AUTOSAR XML (schema 4-3-0)
standard types defined: boolean, float32, float64, sint16, sint32, sint8, uint16, uint32, uint8, uint64, sint64
package /ARPackage_0/Pkg_Cluster
  can cluster Can_Network: protocol-name=CAN
    can physical channel Can_Network_Channel: comm-connectors=[Conn_Can_Network_CANNODE_0_AUT, Conn_Can_Network_CANNODE_0_REF_ECU]
      frame F_STD_0x302: id 0x302, from REF_ECU, to AUT, frame-length=2, can-addressing-mode=STANDARD, can-frame-rx-behavior=ANY
        carries pdu F_STD_0x302: packing-byte-order=big-endian, start-position=0, update-indication-bit-position=-1
        pdu F_STD_0x302: length=2, transmission-mode-condition{data-filter={data-filter-type=NEW-IS-WITHIN, max=32767, min=-32768, offset=0}, i-signal-in-i-pdu=S_STD_0x302_S16}, transmission-mode-false-timing=cyclic-timing={time-offset=0.0, time-period=0.1}, transmission-mode-true-timing=cyclic-timing={time-offset=0.0, time-period=0.1}
          signal S_STD_0x302_S16: start 7, 16 bit, big-endian, base-type=sint16, compu {raw=phys for phys -32768..32767}, update-indication-bit-position=-1, to AUT
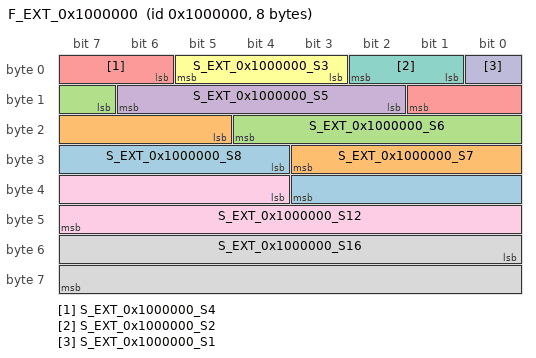
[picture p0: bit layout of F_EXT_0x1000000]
      frame F_EXT_0x1000000: id 0x1000000, from REF_ECU, to AUT, frame-length=8, can-addressing-mode=EXTENDED, can-frame-rx-behavior=ANY
        carries pdu F_EXT_0x1000000: packing-byte-order=little-endian, start-position=0, update-indication-bit-position=-1
        pdu F_EXT_0x1000000: length=8, transmission-mode-false-timing=cyclic-timing={time-offset=0.0, time-period=0.1}, transmission-mode-true-timing=cyclic-timing={time-offset=0.0, time-period=0.1}
          transmission-mode-conditions:
            {data-filter={data-filter-type=ALWAYS, max=255, min=0, offset=0}, i-signal-in-i-pdu=S_EXT_0x1000000_S8}
            {data-filter={data-filter-type=ALWAYS, max=127, min=0, offset=0}, i-signal-in-i-pdu=S_EXT_0x1000000_S7}
            {data-filter={data-filter-type=ALWAYS, max=63, min=0, offset=0}, i-signal-in-i-pdu=S_EXT_0x1000000_S6}
            {data-filter={data-filter-type=ALWAYS, max=31, min=0, offset=0}, i-signal-in-i-pdu=S_EXT_0x1000000_S5}
            {data-filter={data-filter-type=ALWAYS, max=15, min=0, offset=0}, i-signal-in-i-pdu=S_EXT_0x1000000_S4}
            {data-filter={data-filter-type=ALWAYS, max=7, min=0, offset=0}, i-signal-in-i-pdu=S_EXT_0x1000000_S3}
            {data-filter={data-filter-type=ALWAYS, max=3, min=0, offset=0}, i-signal-in-i-pdu=S_EXT_0x1000000_S2}
            {data-filter={data-filter-type=NEW-IS-WITHIN, max=65535, min=0, offset=0}, i-signal-in-i-pdu=S_EXT_0x1000000_S16}
            {data-filter={data-filter-type=NEW-IS-WITHIN, max=4095, min=0, offset=0}, i-signal-in-i-pdu=S_EXT_0x1000000_S12}
            {data-filter={data-filter-type=ALWAYS, max=1, min=0, offset=0}, i-signal-in-i-pdu=S_EXT_0x1000000_S1}
          signal S_EXT_0x1000000_S8: start 28, 8 bit, little-endian, base-type=uint8, compu {raw=phys for phys 0..255}, update-indication-bit-position=-1, to AUT
          signal S_EXT_0x1000000_S7: start 21, 7 bit, little-endian, base-type=uint8, compu {raw=phys for phys 0..127}, update-indication-bit-position=-1, to AUT
          signal S_EXT_0x1000000_S6: start 15, 6 bit, little-endian, base-type=uint8, compu {raw=phys for phys 0..63}, update-indication-bit-position=-1, to AUT
          signal S_EXT_0x1000000_S5: start 10, 5 bit, little-endian, base-type=uint8, compu {raw=phys for phys 0..31}, update-indication-bit-position=-1, to AUT
          signal S_EXT_0x1000000_S4: start 6, 4 bit, little-endian, base-type=uint8, compu {raw=phys for phys 0..15}, update-indication-bit-position=-1, to AUT
          signal S_EXT_0x1000000_S3: start 3, 3 bit, little-endian, base-type=uint8, compu {raw=phys for phys 0..7}, update-indication-bit-position=-1, to AUT
          signal S_EXT_0x1000000_S2: start 1, 2 bit, little-endian, base-type=uint8, compu {raw=phys for phys 0..3}, update-indication-bit-position=-1, to AUT
          signal S_EXT_0x1000000_S16: start 48, 16 bit, little-endian, base-type=uint16, compu {raw=phys for phys 0..65535}, update-indication-bit-position=-1, to AUT
          signal S_EXT_0x1000000_S12: start 36, 12 bit, little-endian, base-type=uint16, compu {raw=phys for phys 0..4095}, update-indication-bit-position=-1, to AUT
          signal S_EXT_0x1000000_S1: start 0, 1 bit, little-endian, base-type=uint8, compu {raw=phys for phys 0..1}, update-indication-bit-position=-1, to AUT
      frame F_STD_0x303: id 0x303, from REF_ECU, to AUT, frame-length=3, can-addressing-mode=STANDARD, can-frame-rx-behavior=ANY
        carries pdu F_STD_0x303: packing-byte-order=big-endian, start-position=0, update-indication-bit-position=-1
        pdu F_STD_0x303: length=3, transmission-mode-condition{data-filter={data-filter-type=NEW-IS-WITHIN, max=8388607, min=-8388608, offset=0}, i-signal-in-i-pdu=S_STD_0x303_S24}, transmission-mode-false-timing=cyclic-timing={time-offset=0.0, time-period=0.1}, transmission-mode-true-timing=cyclic-timing={time-offset=0.0, time-period=0.1}
          signal S_STD_0x303_S24: start 7, 24 bit, big-endian, base-type=sint32, compu {raw=phys for phys -8388608..8388607}, update-indication-bit-position=-1, to AUT
      frame F_STD_0x304: id 0x304, from REF_ECU, to AUT, frame-length=4, can-addressing-mode=STANDARD, can-frame-rx-behavior=ANY
        carries pdu F_STD_0x304: packing-byte-order=big-endian, start-position=0, update-indication-bit-position=-1
        pdu F_STD_0x304: length=4, transmission-mode-condition{data-filter={data-filter-type=NEW-IS-WITHIN, max=4294967295, min=0, offset=0}, i-signal-in-i-pdu=S_STD_0x304_S32}, transmission-mode-false-timing=cyclic-timing={time-offset=0.0, time-period=0.1}, transmission-mode-true-timing=cyclic-timing={time-offset=0.0, time-period=0.1}
          signal S_STD_0x304_S32: start 7, 32 bit, big-endian, base-type=uint32, compu {raw=phys for phys 0..4294967295}, update-indication-bit-position=-1, to AUT
      frame F_STD_0x305: id 0x305, from REF_ECU, to AUT, frame-length=5, can-addressing-mode=STANDARD, can-frame-rx-behavior=ANY
        carries pdu F_STD_0x305: packing-byte-order=big-endian, start-position=0, update-indication-bit-position=-1
        pdu F_STD_0x305: length=5, transmission-mode-false-timing=cyclic-timing={time-offset=0.0, time-period=0.1}, transmission-mode-true-timing=cyclic-timing={time-offset=0.0, time-period=0.1}
          transmission-mode-conditions:
            {data-filter={data-filter-type=ALWAYS, max=255, min=0, offset=0}, i-signal-in-i-pdu=S_STD_0x305_S8}
            {data-filter={data-filter-type=NEW-IS-WITHIN, max=2147483647, min=-2147483648, offset=0}, i-signal-in-i-pdu=S_STD_0x305_S32}
          signal S_STD_0x305_S8: start 39, 8 bit, big-endian, base-type=uint8, compu {raw=phys for phys 0..255}, update-indication-bit-position=-1, to AUT
          signal S_STD_0x305_S32: start 7, 32 bit, big-endian, base-type=sint32, compu {raw=phys for phys -2147483648..2147483647}, update-indication-bit-position=-1, to AUT
      frame F_STD_0x306: id 0x306, from REF_ECU, to AUT, frame-length=6, can-addressing-mode=STANDARD, can-frame-rx-behavior=ANY
        carries pdu F_STD_0x306: packing-byte-order=big-endian, start-position=0, update-indication-bit-position=-1
        pdu F_STD_0x306: length=6, transmission-mode-false-timing=cyclic-timing={time-offset=0.0, time-period=0.1}, transmission-mode-true-timing=cyclic-timing={time-offset=0.0, time-period=0.1}
          transmission-mode-conditions:
            {data-filter={data-filter-type=NEW-IS-WITHIN, max=65535, min=0, offset=0}, i-signal-in-i-pdu=S_STD_0x306_S16}
            {data-filter={data-filter-type=NEW-IS-WITHIN, max=2147483647, min=-2147483648, offset=0}, i-signal-in-i-pdu=S_STD_0x306_S32}
          signal S_STD_0x306_S16: start 39, 16 bit, big-endian, base-type=uint16, compu {raw=phys for phys 0..65535}, update-indication-bit-position=-1, to AUT
          signal S_STD_0x306_S32: start 7, 32 bit, big-endian, base-type=sint32, compu {raw=phys for phys -2147483648..2147483647}, update-indication-bit-position=-1, to AUT
      frame F_STD_0x307: id 0x307, from REF_ECU, to AUT, frame-length=7, can-addressing-mode=STANDARD, can-frame-rx-behavior=ANY
        carries pdu F_STD_0x307: packing-byte-order=big-endian, start-position=0, update-indication-bit-position=-1
        pdu F_STD_0x307: length=7, transmission-mode-false-timing=cyclic-timing={time-offset=0.0, time-period=0.1}, transmission-mode-true-timing=cyclic-timing={time-offset=0.0, time-period=0.1}
          transmission-mode-conditions:
            {data-filter={data-filter-type=NEW-IS-WITHIN, max=8388607, min=-8388608, offset=0}, i-signal-in-i-pdu=S_STD_0x307_S24}
            {data-filter={data-filter-type=NEW-IS-WITHIN, max=2147483647, min=-2147483648, offset=0}, i-signal-in-i-pdu=S_STD_0x307_S32}
          signal S_STD_0x307_S24: start 39, 24 bit, big-endian, base-type=sint32, compu {raw=phys for phys -8388608..8388607}, update-indication-bit-position=-1, to AUT
          signal S_STD_0x307_S32: start 7, 32 bit, big-endian, base-type=sint32, compu {raw=phys for phys -2147483648..2147483647}, update-indication-bit-position=-1, to AUT
      frame F_STD_0x308: id 0x308, from REF_ECU, to AUT, frame-length=8, can-addressing-mode=STANDARD, can-frame-rx-behavior=ANY
        carries pdu F_STD_0x308: packing-byte-order=big-endian, start-position=0, update-indication-bit-position=-1
        pdu F_STD_0x308: length=8, transmission-mode-false-timing=cyclic-timing={time-offset=0.0, time-period=0.1}, transmission-mode-true-timing=cyclic-timing={time-offset=0.0, time-period=0.1}
          transmission-mode-conditions:
            {data-filter={data-filter-type=NEW-IS-WITHIN, max=32767, min=-32768, offset=0}, i-signal-in-i-pdu=S_STD_0x308_2_S32}
            {data-filter={data-filter-type=NEW-IS-WITHIN, max=32767, min=-32768, offset=0}, i-signal-in-i-pdu=S_STD_0x308_1_S32}
          signal S_STD_0x308_2_S32: start 39, 32 bit, big-endian, base-type=sint32, compu {raw=phys for phys -32768..32767}, update-indication-bit-position=-1, to AUT
          signal S_STD_0x308_1_S32: start 0, 32 bit, little-endian, base-type=sint32, compu {raw=phys for phys -32768..32767}, update-indication-bit-position=-1, to AUT
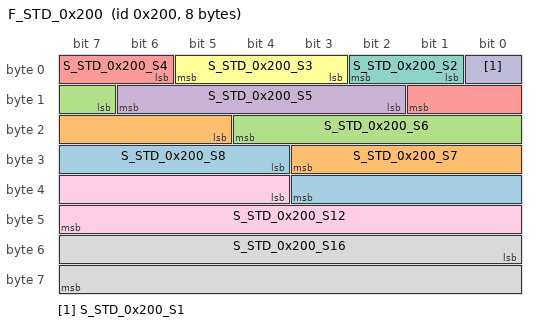
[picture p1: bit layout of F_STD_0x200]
      frame F_STD_0x200: id 0x200, from REF_ECU, to AUT, frame-length=8, can-addressing-mode=STANDARD, can-frame-rx-behavior=ANY
        carries pdu F_STD_0x200: packing-byte-order=little-endian, start-position=0, update-indication-bit-position=-1
        pdu F_STD_0x200: length=8, transmission-mode-false-timing=cyclic-timing={time-offset=0.0, time-period=0.1}, transmission-mode-true-timing=cyclic-timing={time-offset=0.0, time-period=0.1}
          transmission-mode-conditions:
            {data-filter={data-filter-type=ALWAYS, max=255, min=0, offset=0}, i-signal-in-i-pdu=S_STD_0x200_S8}
            {data-filter={data-filter-type=ALWAYS, max=127, min=0, offset=0}, i-signal-in-i-pdu=S_STD_0x200_S7}
            {data-filter={data-filter-type=ALWAYS, max=63, min=0, offset=0}, i-signal-in-i-pdu=S_STD_0x200_S6}
            {data-filter={data-filter-type=ALWAYS, max=31, min=0, offset=0}, i-signal-in-i-pdu=S_STD_0x200_S5}
            {data-filter={data-filter-type=ALWAYS, max=15, min=0, offset=0}, i-signal-in-i-pdu=S_STD_0x200_S4}
            {data-filter={data-filter-type=ALWAYS, max=7, min=0, offset=0}, i-signal-in-i-pdu=S_STD_0x200_S3}
            {data-filter={data-filter-type=ALWAYS, max=3, min=0, offset=0}, i-signal-in-i-pdu=S_STD_0x200_S2}
            {data-filter={data-filter-type=NEW-IS-WITHIN, max=65535, min=0, offset=2}, i-signal-in-i-pdu=S_STD_0x200_S16}
            {data-filter={data-filter-type=NEW-IS-WITHIN, max=4095, min=0, offset=0}, i-signal-in-i-pdu=S_STD_0x200_S12}
            {data-filter={data-filter-type=ALWAYS, max=1, min=0, offset=0}, i-signal-in-i-pdu=S_STD_0x200_S1}
          signal S_STD_0x200_S8: start 28, 8 bit, little-endian, base-type=uint8, compu {raw=phys for phys 0..255}, update-indication-bit-position=-1, to AUT
          signal S_STD_0x200_S7: start 21, 7 bit, little-endian, base-type=uint8, compu {raw=phys for phys 0..127}, update-indication-bit-position=-1, to AUT
          signal S_STD_0x200_S6: start 15, 6 bit, little-endian, base-type=uint8, compu {raw=phys for phys 0..63}, update-indication-bit-position=-1, to AUT
          signal S_STD_0x200_S5: start 10, 5 bit, little-endian, base-type=uint8, compu {raw=phys for phys 0..31}, update-indication-bit-position=-1, to AUT
          signal S_STD_0x200_S4: start 6, 4 bit, little-endian, base-type=uint8, compu {raw=phys for phys 0..15}, update-indication-bit-position=-1, to AUT
          signal S_STD_0x200_S3: start 3, 3 bit, little-endian, base-type=uint8, compu {raw=phys for phys 0..7}, update-indication-bit-position=-1, to AUT
          signal S_STD_0x200_S2: start 1, 2 bit, little-endian, base-type=uint8, compu {raw=phys for phys 0..3}, update-indication-bit-position=-1, to AUT
          signal S_STD_0x200_S16: start 48, 16 bit, little-endian, base-type=uint16, compu {raw=phys*0.5-1 for phys 2..131072}, update-indication-bit-position=-1, to AUT
          signal S_STD_0x200_S12: start 36, 12 bit, little-endian, base-type=uint16, compu {raw=phys for phys 0..4095}, update-indication-bit-position=-1, to AUT
          signal S_STD_0x200_S1: start 0, 1 bit, little-endian, base-type=uint8, compu {raw=phys for phys 0..1}, update-indication-bit-position=-1, to AUT
      frame F_STD_0x201: id 0x201, from REF_ECU, to AUT, frame-length=1, can-addressing-mode=STANDARD, can-frame-rx-behavior=ANY
        carries pdu F_STD_0x201: packing-byte-order=little-endian, start-position=0, update-indication-bit-position=-1
        pdu F_STD_0x201: length=1, transmission-mode-condition{data-filter={data-filter-type=ALWAYS, max=255, min=0, offset=0}, i-signal-in-i-pdu=S_STD_0x201_S8}, transmission-mode-false-timing=cyclic-timing={time-offset=0.0, time-period=0.1}, transmission-mode-true-timing=cyclic-timing={time-offset=0.0, time-period=0.1}
          signal S_STD_0x201_S8: start 0, 8 bit, little-endian, base-type=uint8, compu {raw=phys for phys 0..255}, update-indication-bit-position=-1, to AUT
      frame F_STD_0x202: id 0x202, from REF_ECU, to AUT, frame-length=2, can-addressing-mode=STANDARD, can-frame-rx-behavior=ANY
        carries pdu F_STD_0x202: packing-byte-order=little-endian, start-position=0, update-indication-bit-position=-1
        pdu F_STD_0x202: length=2, transmission-mode-condition{data-filter={data-filter-type=NEW-IS-WITHIN, max=65535, min=0, offset=0}, i-signal-in-i-pdu=S_STD_0x202_S16}, transmission-mode-false-timing=cyclic-timing={time-offset=0.0, time-period=0.1}, transmission-mode-true-timing=cyclic-timing={time-offset=0.0, time-period=0.1}
          signal S_STD_0x202_S16: start 0, 16 bit, little-endian, base-type=uint16, compu {raw=phys for phys 0..65535}, update-indication-bit-position=-1, to AUT
      frame F_STD_0x203: id 0x203, from REF_ECU, to AUT, frame-length=3, can-addressing-mode=STANDARD, can-frame-rx-behavior=ANY
        carries pdu F_STD_0x203: packing-byte-order=little-endian, start-position=0, update-indication-bit-position=-1
        pdu F_STD_0x203: length=3, transmission-mode-condition{data-filter={data-filter-type=NEW-IS-WITHIN, max=16777215, min=0, offset=0}, i-signal-in-i-pdu=S_STD_0x203_S24}, transmission-mode-false-timing=cyclic-timing={time-offset=0.0, time-period=0.1}, transmission-mode-true-timing=cyclic-timing={time-offset=0.0, time-period=0.1}
          signal S_STD_0x203_S24: start 0, 24 bit, little-endian, base-type=uint32, compu {raw=phys for phys 0..16777215}, update-indication-bit-position=-1, to AUT
      frame F_STD_0x204: id 0x204, from REF_ECU, to AUT, frame-length=4, can-addressing-mode=STANDARD, can-frame-rx-behavior=ANY
        carries pdu F_STD_0x204: packing-byte-order=little-endian, start-position=0, update-indication-bit-position=-1
        pdu F_STD_0x204: length=4, transmission-mode-condition{data-filter={data-filter-type=NEW-IS-WITHIN, max=2147483647, min=-2147483648, offset=0}, i-signal-in-i-pdu=S_STD_0x204_S32}, transmission-mode-false-timing=cyclic-timing={time-offset=0.0, time-period=0.1}, transmission-mode-true-timing=cyclic-timing={time-offset=0.0, time-period=0.1}
          signal S_STD_0x204_S32: start 0, 32 bit, little-endian, base-type=sint32, compu {raw=phys for phys -2147483648..2147483647}, update-indication-bit-position=-1, to AUT
      frame F_EXT_0x1000005: id 0x1000005, from REF_ECU, to AUT, frame-length=5, can-addressing-mode=EXTENDED, can-frame-rx-behavior=ANY
        carries pdu F_EXT_0x1000005: packing-byte-order=little-endian, start-position=0, update-indication-bit-position=-1
        pdu F_EXT_0x1000005: length=5, transmission-mode-false-timing=cyclic-timing={time-offset=0.0, time-period=0.1}, transmission-mode-true-timing=cyclic-timing={time-offset=0.0, time-period=0.1}
          transmission-mode-conditions:
            {data-filter={data-filter-type=NEW-IS-WITHIN, max=127, min=-128, offset=0}, i-signal-in-i-pdu=S_EXT_0x1000005_S8}
            {data-filter={data-filter-type=NEW-IS-WITHIN, max=4294967295, min=0, offset=0}, i-signal-in-i-pdu=S_EXT_0x1000005_S32}
          signal S_EXT_0x1000005_S8: start 32, 8 bit, little-endian, base-type=sint8, compu {raw=phys for phys -128..127}, update-indication-bit-position=-1, to AUT
          signal S_EXT_0x1000005_S32: start 0, 32 bit, little-endian, base-type=uint32, compu {raw=phys for phys 0..4294967295}, update-indication-bit-position=-1, to AUT
      frame F_STD_0x205: id 0x205, from REF_ECU, to AUT, frame-length=5, can-addressing-mode=STANDARD, can-frame-rx-behavior=ANY
        carries pdu F_STD_0x205: packing-byte-order=little-endian, start-position=0, update-indication-bit-position=-1
        pdu F_STD_0x205: length=5, transmission-mode-false-timing=cyclic-timing={time-offset=0.0, time-period=0.1}, transmission-mode-true-timing=cyclic-timing={time-offset=0.0, time-period=0.1}
          transmission-mode-conditions:
            {data-filter={data-filter-type=NEW-IS-WITHIN, max=127, min=-128, offset=0}, i-signal-in-i-pdu=S_STD_0x205_S8}
            {data-filter={data-filter-type=NEW-IS-WITHIN, max=4294970000, min=0, offset=0}, i-signal-in-i-pdu=S_STD_0x205_S32}
          signal S_STD_0x205_S8: start 32, 8 bit, little-endian, base-type=sint8, compu {raw=phys for phys -128..127}, update-indication-bit-position=-1, to AUT
          signal S_STD_0x205_S32: start 0, 32 bit, little-endian, base-type=uint32, compu {raw=phys for phys 0..4294970000}, update-indication-bit-position=-1, to AUT
      frame F_EXT_0x1000003: id 0x1000003, from REF_ECU, to AUT, frame-length=3, can-addressing-mode=EXTENDED, can-frame-rx-behavior=ANY
        carries pdu F_EXT_0x1000003: packing-byte-order=little-endian, start-position=0, update-indication-bit-position=-1
        pdu F_EXT_0x1000003: length=3, transmission-mode-condition{data-filter={data-filter-type=NEW-IS-WITHIN, max=16777215, min=0, offset=0}, i-signal-in-i-pdu=S_EXT_0x1000003_S24}, transmission-mode-false-timing=cyclic-timing={time-offset=0.0, time-period=0.1}, transmission-mode-true-timing=cyclic-timing={time-offset=0.0, time-period=0.1}
          signal S_EXT_0x1000003_S24: start 0, 24 bit, little-endian, base-type=uint32, compu {raw=phys for phys 0..16777215}, update-indication-bit-position=-1, to AUT
      frame F_STD_0x206: id 0x206, from REF_ECU, to AUT, frame-length=6, can-addressing-mode=STANDARD, can-frame-rx-behavior=ANY
        carries pdu F_STD_0x206: packing-byte-order=little-endian, start-position=0, update-indication-bit-position=-1
        pdu F_STD_0x206: length=6, transmission-mode-false-timing=cyclic-timing={time-offset=0.0, time-period=0.1}, transmission-mode-true-timing=cyclic-timing={time-offset=0.0, time-period=0.1}
          transmission-mode-conditions:
            {data-filter={data-filter-type=NEW-IS-WITHIN, max=32767, min=-32768, offset=0}, i-signal-in-i-pdu=S_STD_0x206_S16}
            {data-filter={data-filter-type=NEW-IS-WITHIN, max=4294967295, min=0, offset=0}, i-signal-in-i-pdu=S_STD_0x206_S32}
          signal S_STD_0x206_S16: start 32, 16 bit, little-endian, base-type=sint16, compu {raw=phys for phys -32768..32767}, update-indication-bit-position=-1, to AUT
          signal S_STD_0x206_S32: start 0, 32 bit, little-endian, base-type=uint32, compu {raw=phys for phys 0..4294967295}, update-indication-bit-position=-1, to AUT
      frame F_EXT_0x1000004: id 0x1000004, from REF_ECU, to AUT, frame-length=4, can-addressing-mode=EXTENDED, can-frame-rx-behavior=ANY
        carries pdu F_EXT_0x1000004: packing-byte-order=little-endian, start-position=0, update-indication-bit-position=-1
        pdu F_EXT_0x1000004: length=4, transmission-mode-condition{data-filter={data-filter-type=NEW-IS-WITHIN, max=2147483647, min=-2147483648, offset=0}, i-signal-in-i-pdu=S_EXT_0x1000004_S32}, transmission-mode-false-timing=cyclic-timing={time-offset=0.0, time-period=0.1}, transmission-mode-true-timing=cyclic-timing={time-offset=0.0, time-period=0.1}
          signal S_EXT_0x1000004_S32: start 0, 32 bit, little-endian, base-type=sint32, compu {raw=phys for phys -2147483648..2147483647}, update-indication-bit-position=-1, to AUT
      frame F_STD_0x207: id 0x207, from REF_ECU, to AUT, frame-length=7, can-addressing-mode=STANDARD, can-frame-rx-behavior=ANY
        carries pdu F_STD_0x207: packing-byte-order=little-endian, start-position=0, update-indication-bit-position=-1
        pdu F_STD_0x207: length=7, transmission-mode-false-timing=cyclic-timing={time-offset=0.0, time-period=0.1}, transmission-mode-true-timing=cyclic-timing={time-offset=0.0, time-period=0.1}
          transmission-mode-conditions:
            {data-filter={data-filter-type=NEW-IS-WITHIN, max=16777215, min=0, offset=0}, i-signal-in-i-pdu=S_STD_0x207_S24}
            {data-filter={data-filter-type=NEW-IS-WITHIN, max=4294970000, min=0, offset=0}, i-signal-in-i-pdu=S_STD_0x207_S32}
          signal S_STD_0x207_S24: start 32, 24 bit, little-endian, base-type=uint32, compu {raw=phys for phys 0..16777215}, update-indication-bit-position=-1, to AUT
          signal S_STD_0x207_S32: start 0, 32 bit, little-endian, base-type=uint32, compu {raw=phys for phys 0..4294970000}, update-indication-bit-position=-1, to AUT
      frame F_EXT_0x1000001: id 0x1000001, from REF_ECU, to AUT, frame-length=1, can-addressing-mode=EXTENDED, can-frame-rx-behavior=ANY
        carries pdu F_EXT_0x1000001: packing-byte-order=little-endian, start-position=0, update-indication-bit-position=-1
        pdu F_EXT_0x1000001: length=1, transmission-mode-condition{data-filter={data-filter-type=ALWAYS, max=255, min=0, offset=0}, i-signal-in-i-pdu=S_EXT_0x1000001_S8}, transmission-mode-false-timing=cyclic-timing={time-offset=0.0, time-period=0.1}, transmission-mode-true-timing=cyclic-timing={time-offset=0.0, time-period=0.1}
          signal S_EXT_0x1000001_S8: start 0, 8 bit, little-endian, base-type=uint8, compu {raw=phys for phys 0..255}, update-indication-bit-position=-1, to AUT
      frame F_EXT_0x1000002: id 0x1000002, from REF_ECU, to AUT, frame-length=2, can-addressing-mode=EXTENDED, can-frame-rx-behavior=ANY
        carries pdu F_EXT_0x1000002: packing-byte-order=little-endian, start-position=0, update-indication-bit-position=-1
        pdu F_EXT_0x1000002: length=2, transmission-mode-condition{data-filter={data-filter-type=NEW-IS-WITHIN, max=65535, min=0, offset=0}, i-signal-in-i-pdu=S_EXT_0x1000002_S16}, transmission-mode-false-timing=cyclic-timing={time-offset=0.0, time-period=0.1}, transmission-mode-true-timing=cyclic-timing={time-offset=0.0, time-period=0.1}
          signal S_EXT_0x1000002_S16: start 0, 16 bit, little-endian, base-type=uint16, compu {raw=phys for phys 0..65535}, update-indication-bit-position=-1, to AUT
      frame F_EXT_0x2000006: id 0x2000006, from REF_ECU, to AUT, frame-length=6, can-addressing-mode=EXTENDED, can-frame-rx-behavior=ANY
        carries pdu F_EXT_0x2000006: packing-byte-order=big-endian, start-position=0, update-indication-bit-position=-1
        pdu F_EXT_0x2000006: length=6, transmission-mode-false-timing=cyclic-timing={time-offset=0.0, time-period=0.1}, transmission-mode-true-timing=cyclic-timing={time-offset=0.0, time-period=0.1}
          transmission-mode-conditions:
            {data-filter={data-filter-type=NEW-IS-WITHIN, max=65535, min=0, offset=0}, i-signal-in-i-pdu=S_EXT_0x2000006_S16}
            {data-filter={data-filter-type=NEW-IS-WITHIN, max=2147483647, min=-2147483648, offset=0}, i-signal-in-i-pdu=S_EXT_0x2000006_S32}
          signal S_EXT_0x2000006_S16: start 39, 16 bit, big-endian, base-type=uint16, compu {raw=phys for phys 0..65535}, update-indication-bit-position=-1, to AUT
          signal S_EXT_0x2000006_S32: start 7, 32 bit, big-endian, base-type=sint32, compu {raw=phys for phys -2147483648..2147483647}, update-indication-bit-position=-1, to AUT
      frame F_EXT_0x2000005: id 0x2000005, from REF_ECU, to AUT, frame-length=5, can-addressing-mode=EXTENDED, can-frame-rx-behavior=ANY
        carries pdu F_EXT_0x2000005: packing-byte-order=big-endian, start-position=0, update-indication-bit-position=-1
        pdu F_EXT_0x2000005: length=5, transmission-mode-false-timing=cyclic-timing={time-offset=0.0, time-period=0.1}, transmission-mode-true-timing=cyclic-timing={time-offset=0.0, time-period=0.1}
          transmission-mode-conditions:
            {data-filter={data-filter-type=ALWAYS, max=255, min=0, offset=0}, i-signal-in-i-pdu=S_EXT_0x2000005_S8}
            {data-filter={data-filter-type=NEW-IS-WITHIN, max=2147483647, min=-2147483648, offset=0}, i-signal-in-i-pdu=S_EXT_0x2000005_S32}
          signal S_EXT_0x2000005_S8: start 39, 8 bit, big-endian, base-type=uint8, compu {raw=phys for phys 0..255}, update-indication-bit-position=-1, to AUT
          signal S_EXT_0x2000005_S32: start 7, 32 bit, big-endian, base-type=sint32, compu {raw=phys for phys -2147483648..2147483647}, update-indication-bit-position=-1, to AUT
      frame F_EXT_0x2000008: id 0x2000008, from REF_ECU, to AUT, frame-length=8, can-addressing-mode=EXTENDED, can-frame-rx-behavior=ANY
        carries pdu F_EXT_0x2000008: packing-byte-order=big-endian, start-position=0, update-indication-bit-position=-1
        pdu F_EXT_0x2000008: length=8, transmission-mode-false-timing=cyclic-timing={time-offset=0.0, time-period=0.1}, transmission-mode-true-timing=cyclic-timing={time-offset=0.0, time-period=0.1}
          transmission-mode-conditions:
            {data-filter={data-filter-type=NEW-IS-WITHIN, max=32767, min=-32768, offset=0}, i-signal-in-i-pdu=S_EXT_0x2000008_2_S32}
            {data-filter={data-filter-type=NEW-IS-WITHIN, max=32767, min=-32768, offset=0}, i-signal-in-i-pdu=S_EXT_0x2000008_1_S32}
          signal S_EXT_0x2000008_2_S32: start 39, 32 bit, big-endian, base-type=sint32, compu {raw=phys for phys -32768..32767}, update-indication-bit-position=-1, to AUT
          signal S_EXT_0x2000008_1_S32: start 0, 32 bit, little-endian, base-type=sint32, compu {raw=phys for phys -32768..32767}, update-indication-bit-position=-1, to AUT
      frame F_EXT_0x2000007: id 0x2000007, from REF_ECU, to AUT, frame-length=7, can-addressing-mode=EXTENDED, can-frame-rx-behavior=ANY
        carries pdu F_EXT_0x2000007: packing-byte-order=big-endian, start-position=0, update-indication-bit-position=-1
        pdu F_EXT_0x2000007: length=7, transmission-mode-false-timing=cyclic-timing={time-offset=0.0, time-period=0.1}, transmission-mode-true-timing=cyclic-timing={time-offset=0.0, time-period=0.1}
          transmission-mode-conditions:
            {data-filter={data-filter-type=NEW-IS-WITHIN, max=8388607, min=-8388608, offset=0}, i-signal-in-i-pdu=S_EXT_0x2000007_S24}
            {data-filter={data-filter-type=NEW-IS-WITHIN, max=2147483647, min=-2147483648, offset=0}, i-signal-in-i-pdu=S_EXT_0x2000007_S32}
          signal S_EXT_0x2000007_S24: start 39, 24 bit, big-endian, base-type=sint32, compu {raw=phys for phys -8388608..8388607}, update-indication-bit-position=-1, to AUT
          signal S_EXT_0x2000007_S32: start 7, 32 bit, big-endian, base-type=sint32, compu {raw=phys for phys -2147483648..2147483647}, update-indication-bit-position=-1, to AUT
      frame F_EXT_0x1000008: id 0x1000008, from REF_ECU, to AUT, frame-length=8, can-addressing-mode=EXTENDED, can-frame-rx-behavior=ANY
        carries pdu F_EXT_0x1000008: packing-byte-order=little-endian, start-position=0, update-indication-bit-position=-1
        pdu F_EXT_0x1000008: length=8, transmission-mode-false-timing=cyclic-timing={time-offset=0.0, time-period=0.1}, transmission-mode-true-timing=cyclic-timing={time-offset=0.0, time-period=0.1}
          transmission-mode-conditions:
            {data-filter={data-filter-type=NEW-IS-WITHIN, max=4294967295, min=0, offset=0}, i-signal-in-i-pdu=S_EXT_0x1000008_2_S32}
            {data-filter={data-filter-type=NEW-IS-WITHIN, max=4294970000, min=0, offset=0}, i-signal-in-i-pdu=S_EXT_0x1000008_1_S32}
          signal S_EXT_0x1000008_2_S32: start 32, 32 bit, little-endian, base-type=uint32, compu {raw=phys for phys 0..4294967295}, update-indication-bit-position=-1, to AUT
          signal S_EXT_0x1000008_1_S32: start 0, 32 bit, little-endian, base-type=uint32, compu {raw=phys for phys 0..4294970000}, update-indication-bit-position=-1, to AUT
      frame F_STD_0x208: id 0x208, from REF_ECU, to AUT, frame-length=8, can-addressing-mode=STANDARD, can-frame-rx-behavior=ANY
        carries pdu F_STD_0x208: packing-byte-order=little-endian, start-position=0, update-indication-bit-position=-1
        pdu F_STD_0x208: length=8, transmission-mode-false-timing=cyclic-timing={time-offset=0.0, time-period=0.1}, transmission-mode-true-timing=cyclic-timing={time-offset=0.0, time-period=0.1}
          transmission-mode-conditions:
            {data-filter={data-filter-type=NEW-IS-WITHIN, max=4294970000, min=0, offset=0}, i-signal-in-i-pdu=S_STD_0x208_2_S32}
            {data-filter={data-filter-type=NEW-IS-WITHIN, max=2147484998, min=0, offset=4}, i-signal-in-i-pdu=S_STD_0x208_1_S32}
          signal S_STD_0x208_2_S32: start 32, 32 bit, little-endian, base-type=uint32, compu {raw=phys for phys 0..4294970000}, update-indication-bit-position=-1, to AUT
          signal S_STD_0x208_1_S32: start 0, 32 bit, little-endian, base-type=uint32, compu {raw=phys*0.5-2 for phys 4..4294970000}, update-indication-bit-position=-1, to AUT
      frame F_EXT_0x1000006: id 0x1000006, from REF_ECU, to AUT, frame-length=6, can-addressing-mode=EXTENDED, can-frame-rx-behavior=ANY
        carries pdu F_EXT_0x1000006: packing-byte-order=little-endian, start-position=0, update-indication-bit-position=-1
        pdu F_EXT_0x1000006: length=6, transmission-mode-false-timing=cyclic-timing={time-offset=0.0, time-period=0.1}, transmission-mode-true-timing=cyclic-timing={time-offset=0.0, time-period=0.1}
          transmission-mode-conditions:
            {data-filter={data-filter-type=NEW-IS-WITHIN, max=32767, min=-32768, offset=0}, i-signal-in-i-pdu=S_EXT_0x1000006_S16}
            {data-filter={data-filter-type=NEW-IS-WITHIN, max=4294967295, min=0, offset=0}, i-signal-in-i-pdu=S_EXT_0x1000006_S32}
          signal S_EXT_0x1000006_S16: start 32, 16 bit, little-endian, base-type=sint16, compu {raw=phys for phys -32768..32767}, update-indication-bit-position=-1, to AUT
          signal S_EXT_0x1000006_S32: start 0, 32 bit, little-endian, base-type=uint32, compu {raw=phys for phys 0..4294967295}, update-indication-bit-position=-1, to AUT
      frame F_EXT_0x1000007: id 0x1000007, from REF_ECU, to AUT, frame-length=7, can-addressing-mode=EXTENDED, can-frame-rx-behavior=ANY
        carries pdu F_EXT_0x1000007: packing-byte-order=little-endian, start-position=0, update-indication-bit-position=-1
        pdu F_EXT_0x1000007: length=7, transmission-mode-false-timing=cyclic-timing={time-offset=0.0, time-period=0.1}, transmission-mode-true-timing=cyclic-timing={time-offset=0.0, time-period=0.1}
          transmission-mode-conditions:
            {data-filter={data-filter-type=NEW-IS-WITHIN, max=16777215, min=0, offset=0}, i-signal-in-i-pdu=S_EXT_0x1000007_S24}
            {data-filter={data-filter-type=NEW-IS-WITHIN, max=4294967295, min=0, offset=0}, i-signal-in-i-pdu=S_EXT_0x1000007_S32}
          signal S_EXT_0x1000007_S24: start 32, 24 bit, little-endian, base-type=uint32, compu {raw=phys for phys 0..16777215}, update-indication-bit-position=-1, to AUT
          signal S_EXT_0x1000007_S32: start 0, 32 bit, little-endian, base-type=uint32, compu {raw=phys for phys 0..4294967295}, update-indication-bit-position=-1, to AUT
      frame F_EXT_0x2000002: id 0x2000002, from REF_ECU, to AUT, frame-length=2, can-addressing-mode=EXTENDED, can-frame-rx-behavior=ANY
        carries pdu F_EXT_0x2000002: packing-byte-order=big-endian, start-position=0, update-indication-bit-position=-1
        pdu F_EXT_0x2000002: length=2, transmission-mode-condition{data-filter={data-filter-type=NEW-IS-WITHIN, max=32767, min=-32768, offset=0}, i-signal-in-i-pdu=S_EXT_0x2000002_S16}, transmission-mode-false-timing=cyclic-timing={time-offset=0.0, time-period=0.1}, transmission-mode-true-timing=cyclic-timing={time-offset=0.0, time-period=0.1}
          signal S_EXT_0x2000002_S16: start 7, 16 bit, big-endian, base-type=sint16, compu {raw=phys for phys -32768..32767}, update-indication-bit-position=-1, to AUT
      frame F_EXT_0x2000001: id 0x2000001, from REF_ECU, to AUT, frame-length=1, can-addressing-mode=EXTENDED, can-frame-rx-behavior=ANY
        carries pdu F_EXT_0x2000001: packing-byte-order=big-endian, start-position=0, update-indication-bit-position=-1
        pdu F_EXT_0x2000001: length=1, transmission-mode-condition{data-filter={data-filter-type=NEW-IS-WITHIN, max=127, min=-128, offset=0}, i-signal-in-i-pdu=S_EXT_0x2000001_S8}, transmission-mode-false-timing=cyclic-timing={time-offset=0.0, time-period=0.1}, transmission-mode-true-timing=cyclic-timing={time-offset=0.0, time-period=0.1}
          signal S_EXT_0x2000001_S8: start 7, 8 bit, big-endian, base-type=sint8, compu {raw=phys for phys -128..127}, update-indication-bit-position=-1, to AUT
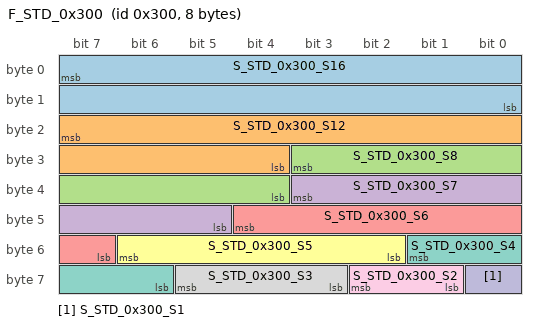
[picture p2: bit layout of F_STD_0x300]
      frame F_STD_0x300: id 0x300, from REF_ECU, to AUT, frame-length=8, can-addressing-mode=STANDARD, can-frame-rx-behavior=ANY
        carries pdu F_STD_0x300: packing-byte-order=big-endian, start-position=0, update-indication-bit-position=-1
        pdu F_STD_0x300: length=8, transmission-mode-false-timing=cyclic-timing={time-offset=0.0, time-period=0.1}, transmission-mode-true-timing=cyclic-timing={time-offset=0.0, time-period=0.1}
          transmission-mode-conditions:
            {data-filter={data-filter-type=NEW-IS-WITHIN, max=32767, min=-32768, offset=0}, i-signal-in-i-pdu=S_STD_0x300_S16}
            {data-filter={data-filter-type=NEW-IS-WITHIN, max=2047, min=-2048, offset=0}, i-signal-in-i-pdu=S_STD_0x300_S12}
            {data-filter={data-filter-type=NEW-IS-WITHIN, max=127, min=-128, offset=0}, i-signal-in-i-pdu=S_STD_0x300_S8}
            {data-filter={data-filter-type=NEW-IS-WITHIN, max=63, min=-64, offset=0}, i-signal-in-i-pdu=S_STD_0x300_S7}
            {data-filter={data-filter-type=NEW-IS-WITHIN, max=31, min=-32, offset=0}, i-signal-in-i-pdu=S_STD_0x300_S6}
            {data-filter={data-filter-type=NEW-IS-WITHIN, max=15, min=-16, offset=0}, i-signal-in-i-pdu=S_STD_0x300_S5}
            {data-filter={data-filter-type=NEW-IS-WITHIN, max=7, min=-8, offset=0}, i-signal-in-i-pdu=S_STD_0x300_S4}
            {data-filter={data-filter-type=NEW-IS-WITHIN, max=3, min=-4, offset=0}, i-signal-in-i-pdu=S_STD_0x300_S3}
            {data-filter={data-filter-type=NEW-IS-WITHIN, max=1, min=-2, offset=0}, i-signal-in-i-pdu=S_STD_0x300_S2}
            {data-filter={data-filter-type=NEW-IS-WITHIN, max=0, min=-1, offset=0}, i-signal-in-i-pdu=S_STD_0x300_S1}
          signal S_STD_0x300_S16: start 7, 16 bit, big-endian, base-type=sint16, compu {raw=phys for phys -32768..32767}, update-indication-bit-position=-1, to AUT
          signal S_STD_0x300_S12: start 23, 12 bit, big-endian, base-type=sint16, compu {raw=phys for phys -2048..2047}, update-indication-bit-position=-1, to AUT
          signal S_STD_0x300_S8: start 27, 8 bit, big-endian, base-type=sint8, compu {raw=phys for phys -128..127}, update-indication-bit-position=-1, to AUT
          signal S_STD_0x300_S7: start 35, 7 bit, big-endian, base-type=sint8, compu {raw=phys for phys -64..63}, update-indication-bit-position=-1, to AUT
          signal S_STD_0x300_S6: start 44, 6 bit, big-endian, base-type=sint8, compu {raw=phys for phys -32..31}, update-indication-bit-position=-1, to AUT
          signal S_STD_0x300_S5: start 54, 5 bit, big-endian, base-type=sint8, compu {raw=phys for phys -16..15}, update-indication-bit-position=-1, to AUT
          signal S_STD_0x300_S4: start 49, 4 bit, big-endian, base-type=sint8, compu {raw=phys for phys -8..7}, update-indication-bit-position=-1, to AUT
          signal S_STD_0x300_S3: start 61, 3 bit, big-endian, base-type=sint8, compu {raw=phys for phys -4..3}, update-indication-bit-position=-1, to AUT
          signal S_STD_0x300_S2: start 58, 2 bit, big-endian, base-type=sint8, compu {raw=phys for phys -2..1}, update-indication-bit-position=-1, to AUT
          signal S_STD_0x300_S1: start 56, 1 bit, big-endian, base-type=sint8, compu {raw=phys for phys -1..0}, update-indication-bit-position=-1, to AUT
      frame F_EXT_0x2000004: id 0x2000004, from REF_ECU, to AUT, frame-length=4, can-addressing-mode=EXTENDED, can-frame-rx-behavior=ANY
        carries pdu F_EXT_0x2000004: packing-byte-order=big-endian, start-position=0, update-indication-bit-position=-1
        pdu F_EXT_0x2000004: length=4, transmission-mode-condition{data-filter={data-filter-type=NEW-IS-WITHIN, max=4294967295, min=0, offset=0}, i-signal-in-i-pdu=S_EXT_0x2000004_S32}, transmission-mode-false-timing=cyclic-timing={time-offset=0.0, time-period=0.1}, transmission-mode-true-timing=cyclic-timing={time-offset=0.0, time-period=0.1}
          signal S_EXT_0x2000004_S32: start 7, 32 bit, big-endian, base-type=uint32, compu {raw=phys for phys 0..4294967295}, update-indication-bit-position=-1, to AUT
      frame F_STD_0x301: id 0x301, from REF_ECU, to AUT, frame-length=1, can-addressing-mode=STANDARD, can-frame-rx-behavior=ANY
        carries pdu F_STD_0x301: packing-byte-order=big-endian, start-position=0, update-indication-bit-position=-1
        pdu F_STD_0x301: length=1, transmission-mode-condition{data-filter={data-filter-type=NEW-IS-WITHIN, max=127, min=-128, offset=0}, i-signal-in-i-pdu=S_STD_0x301_S8}, transmission-mode-false-timing=cyclic-timing={time-offset=0.0, time-period=0.1}, transmission-mode-true-timing=cyclic-timing={time-offset=0.0, time-period=0.1}
          signal S_STD_0x301_S8: start 7, 8 bit, big-endian, base-type=sint8, compu {raw=phys for phys -128..127}, update-indication-bit-position=-1, to AUT
      frame F_EXT_0x2000003: id 0x2000003, from REF_ECU, to AUT, frame-length=3, can-addressing-mode=EXTENDED, can-frame-rx-behavior=ANY
        carries pdu F_EXT_0x2000003: packing-byte-order=big-endian, start-position=0, update-indication-bit-position=-1
        pdu F_EXT_0x2000003: length=3, transmission-mode-condition{data-filter={data-filter-type=NEW-IS-WITHIN, max=8388607, min=-8388608, offset=0}, i-signal-in-i-pdu=S_EXT_0x2000003_S24}, transmission-mode-false-timing=cyclic-timing={time-offset=0.0, time-period=0.1}, transmission-mode-true-timing=cyclic-timing={time-offset=0.0, time-period=0.1}
          signal S_EXT_0x2000003_S24: start 7, 24 bit, big-endian, base-type=sint32, compu {raw=phys for phys -8388608..8388607}, update-indication-bit-position=-1, to AUT
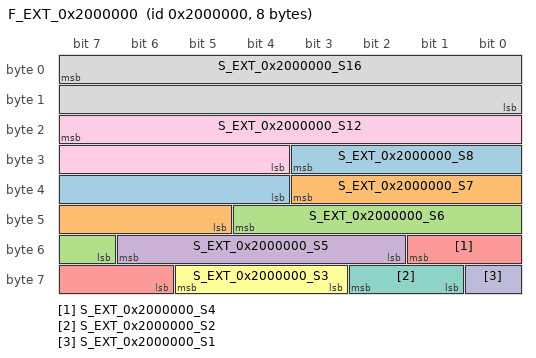
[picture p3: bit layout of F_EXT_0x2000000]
      frame F_EXT_0x2000000: id 0x2000000, from REF_ECU, to AUT, frame-length=8, can-addressing-mode=EXTENDED, can-frame-rx-behavior=ANY
        carries pdu F_EXT_0x2000000: packing-byte-order=big-endian, start-position=0, update-indication-bit-position=-1
        pdu F_EXT_0x2000000: length=8, transmission-mode-false-timing=cyclic-timing={time-offset=0.0, time-period=0.1}, transmission-mode-true-timing=cyclic-timing={time-offset=0.0, time-period=0.1}
          transmission-mode-conditions:
            {data-filter={data-filter-type=NEW-IS-WITHIN, max=127, min=-128, offset=0}, i-signal-in-i-pdu=S_EXT_0x2000000_S8}
            {data-filter={data-filter-type=NEW-IS-WITHIN, max=63, min=-64, offset=0}, i-signal-in-i-pdu=S_EXT_0x2000000_S7}
            {data-filter={data-filter-type=NEW-IS-WITHIN, max=31, min=-32, offset=0}, i-signal-in-i-pdu=S_EXT_0x2000000_S6}
            {data-filter={data-filter-type=NEW-IS-WITHIN, max=15, min=-16, offset=0}, i-signal-in-i-pdu=S_EXT_0x2000000_S5}
            {data-filter={data-filter-type=NEW-IS-WITHIN, max=7, min=-8, offset=0}, i-signal-in-i-pdu=S_EXT_0x2000000_S4}
            {data-filter={data-filter-type=NEW-IS-WITHIN, max=3, min=-4, offset=0}, i-signal-in-i-pdu=S_EXT_0x2000000_S3}
            {data-filter={data-filter-type=NEW-IS-WITHIN, max=1, min=-2, offset=0}, i-signal-in-i-pdu=S_EXT_0x2000000_S2}
            {data-filter={data-filter-type=NEW-IS-WITHIN, max=32767, min=-32768, offset=0}, i-signal-in-i-pdu=S_EXT_0x2000000_S16}
            {data-filter={data-filter-type=NEW-IS-WITHIN, max=2047, min=-2048, offset=0}, i-signal-in-i-pdu=S_EXT_0x2000000_S12}
            {data-filter={data-filter-type=NEW-IS-WITHIN, max=0, min=-1, offset=0}, i-signal-in-i-pdu=S_EXT_0x2000000_S1}
          signal S_EXT_0x2000000_S8: start 27, 8 bit, big-endian, base-type=sint8, compu {raw=phys for phys -128..127}, update-indication-bit-position=-1, to AUT
          signal S_EXT_0x2000000_S7: start 35, 7 bit, big-endian, base-type=sint8, compu {raw=phys for phys -64..63}, update-indication-bit-position=-1, to AUT
          signal S_EXT_0x2000000_S6: start 44, 6 bit, big-endian, base-type=sint8, compu {raw=phys for phys -32..31}, update-indication-bit-position=-1, to AUT
          signal S_EXT_0x2000000_S5: start 54, 5 bit, big-endian, base-type=sint8, compu {raw=phys for phys -16..15}, update-indication-bit-position=-1, to AUT
          signal S_EXT_0x2000000_S4: start 49, 4 bit, big-endian, base-type=sint8, compu {raw=phys for phys -8..7}, update-indication-bit-position=-1, to AUT
          signal S_EXT_0x2000000_S3: start 61, 3 bit, big-endian, base-type=sint8, compu {raw=phys for phys -4..3}, update-indication-bit-position=-1, to AUT
          signal S_EXT_0x2000000_S2: start 58, 2 bit, big-endian, base-type=sint8, compu {raw=phys for phys -2..1}, update-indication-bit-position=-1, to AUT
          signal S_EXT_0x2000000_S16: start 7, 16 bit, big-endian, base-type=sint16, compu {raw=phys for phys -32768..32767}, update-indication-bit-position=-1, to AUT
          signal S_EXT_0x2000000_S12: start 23, 12 bit, big-endian, base-type=sint16, compu {raw=phys for phys -2048..2047}, update-indication-bit-position=-1, to AUT
          signal S_EXT_0x2000000_S1: start 56, 1 bit, big-endian, base-type=sint8, compu {raw=phys for phys -1..0}, update-indication-bit-position=-1, to AUT
package /ARPackage_0/Pkg_Ecu
  ecu instance AUT: com-configuration-gw-time-base=0.005, com-configuration-rx-time-base=0.01, com-configuration-tx-time-base=0.01, sleep-mode-supported=false, wake-up-over-bus-supported=false
    can communication controller Can_Network_CANNODE_0: can-controller-attributes=can-controller-configuration={can-controller-fd-attributes={prop-seg=0, sync-jump-width=0, time-seg-1=10, time-seg-2=0}, prop-seg=0, sync-jump-width=0, time-seg-1=10, time-seg-2=0}
    can communication connector Conn_Can_Network_CANNODE_0_AUT: comm-controller=AUT/Can_Network_CANNODE_0
  ecu instance REF_ECU: com-configuration-gw-time-base=0.005, com-configuration-rx-time-base=0.01, com-configuration-tx-time-base=0.01, sleep-mode-supported=false, wake-up-over-bus-supported=false
    can communication controller Can_Network_CANNODE_0: can-controller-attributes=can-controller-configuration={can-controller-fd-attributes={prop-seg=0, sync-jump-width=0, time-seg-1=10, time-seg-2=0}, prop-seg=0, sync-jump-width=0, time-seg-1=10, time-seg-2=0}
    can communication connector Conn_Can_Network_CANNODE_0_REF_ECU: comm-controller=REF_ECU/Can_Network_CANNODE_0
package /AUTOSAR_PlatformTypes/ImplementationDataTypes  # AUTOSAR platform types
package /AUTOSAR_PlatformTypes/SwBaseTypes  # AUTOSAR platform types
package /AUTOSAR_PlatformTypes/DataConstraints  # AUTOSAR platform types
  range DataConstr_uint8: phys 0..255, raw 0..255
  range DataConstr_uint16: phys 0..65535, raw 0..65535
  range DataConstr_uint32: phys 0..4294967295, raw 0..4294967295
  range DataConstr_sint8: phys -128..127, raw -128..127
  range DataConstr_sint16: phys -32768..32767, raw -32768..32767
  range DataConstr_sint32: phys -2147483648..2147483647, raw -2147483648..2147483647
  range DataConstr_boolean: phys 0..1, raw 0..1
  range DataConstr_sint64: phys -9223372036854775808..9223372036854775807, raw -9223372036854775808..9223372036854775807
  range DataConstr_uint64: phys 0..18446744073709551615, raw 0..18446744073709551615
